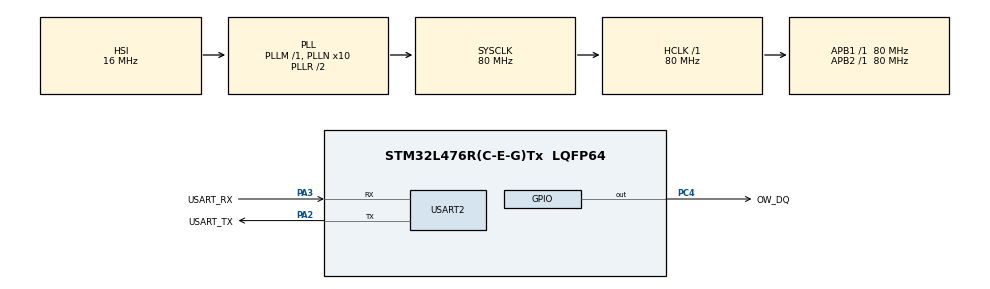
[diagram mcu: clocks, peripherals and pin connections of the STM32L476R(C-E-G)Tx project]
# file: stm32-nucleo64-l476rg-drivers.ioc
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Mcu.Family=STM32L4
Mcu.Name=STM32L476R(C-E-G)Tx
Mcu.Package=LQFP64
NVIC.PriorityGroup=NVIC_PRIORITYGROUP_4
PA13\ (JTMS-SWDIO).GPIO_Label=TMS
PA13\ (JTMS-SWDIO).Mode=Serial_Wire
PA13\ (JTMS-SWDIO).Signal=SYS_JTMS-SWDIO
PA14\ (JTCK-SWCLK).GPIO_Label=TCK
PA14\ (JTCK-SWCLK).Mode=Serial_Wire
PA14\ (JTCK-SWCLK).Signal=SYS_JTCK-SWCLK
PA2.GPIO_Label=USART_TX
PA2.GPIO_Mode=GPIO_MODE_AF_PP
PA2.GPIO_PuPd=GPIO_NOPULL
PA2.GPIO_Speed=GPIO_SPEED_FREQ_VERY_HIGH
PA2.Mode=Asynchronous
PA2.Signal=USART2_TX
PA3.GPIO_Label=USART_RX
PA3.GPIO_Mode=GPIO_MODE_AF_PP
PA3.GPIO_PuPd=GPIO_NOPULL
PA3.GPIO_Speed=GPIO_SPEED_FREQ_VERY_HIGH
PA3.Mode=Asynchronous
PA3.Signal=USART2_RX
PB3\ (JTDO-TRACESWO).GPIO_Label=SWO
PB3\ (JTDO-TRACESWO).Signal=SYS_JTDO-SWO
PC14-OSC32_IN\ (PC14).Mode=LSE-External-Oscillator
PC14-OSC32_IN\ (PC14).Signal=RCC_OSC32_IN
PC15-OSC32_OUT\ (PC15).Mode=LSE-External-Oscillator
PC15-OSC32_OUT\ (PC15).Signal=RCC_OSC32_OUT
PC4.GPIO_Label=OW_DQ
PC4.GPIO_ModeDefaultOutputPP=GPIO_MODE_OUTPUT_OD
PC4.GPIO_PuPd=GPIO_NOPULL
PC4.PinState=GPIO_PIN_SET
PC4.Signal=GPIO_Output
PH0-OSC_IN\ (PH0).Signal=RCC_OSC_IN
PH1-OSC_OUT\ (PH1).Signal=RCC_OSC_OUT
ProjectManager.HeapSize=0x200
ProjectManager.StackSize=0x400
ProjectManager.TargetToolchain=CMake
RCC.ADCFreq_Value=64000000
RCC.AHBFreq_Value=80000000
RCC.APB1Freq_Value=80000000
RCC.APB1TimFreq_Value=80000000
RCC.APB2Freq_Value=80000000
RCC.APB2TimFreq_Value=80000000
RCC.CortexFreq_Value=80000000
RCC.HCLKFreq_Value=80000000
RCC.HSE_VALUE=8000000
RCC.HSI_VALUE=16000000
RCC.MSI_VALUE=4000000
RCC.PLLN=10
RCC.PLLSourceVirtual=RCC_PLLSOURCE_HSI
RCC.PREFETCH_ENABLE=1
RCC.SYSCLKFreq_VALUE=80000000
RCC.SYSCLKSource=RCC_SYSCLKSOURCE_PLLCLK
RCC.USBFreq_Value=64000000
RCC.VCOOutputFreq_Value=160000000
USART2.VirtualMode-Asynchronous=VM_ASYNC
board=NUCLEO-L476RG

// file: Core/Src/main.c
/* USER CODE BEGIN Header */
/**
 ******************************************************************************
 * @file           : main.c
 * @brief          : Main program body
 ******************************************************************************
 * @attention
 *
 * Copyright (c) 2025 STMicroelectronics.
 * All rights reserved.
 *
 * This software is licensed under terms that can be found in the LICENSE file
 * in the root directory of this software component.
 * If no LICENSE file comes with this software, it is provided AS-IS.
 *
 ******************************************************************************
 */
/* USER CODE END Header */
#include "main.h"
#include "gpio.h"
#include "usart.h"

/* USER CODE BEGIN Includes */
#include "ds18b20.h"
#include "one_wire.h"
#include <stdint.h>
#include <stdio.h>

/* USER CODE END Includes */

/* USER CODE BEGIN PD */
#define MAX_ONE_WIRE_DEVICES 10
/* USER CODE END PD */

void SystemClock_Config(void);

/* USER CODE BEGIN 0 */
// Printf redirect to UART
int _write(int file, char *ptr, int len) {
  HAL_UART_Transmit(&huart2, (uint8_t *)ptr, len, HAL_MAX_DELAY);
  return len;
}

/* USER CODE END 0 */

int main(void) {

  /* MCU Configuration--------------------------------------------------------*/

  /* Reset of all peripherals, Initializes the Flash interface and the Systick.
   */
  HAL_Init();

  /* USER CODE BEGIN Init */
  ds18b20_init();
  /* USER CODE END Init */

  /* Configure the system clock */
  SystemClock_Config();

  /* Initialize all configured peripherals */
  MX_GPIO_Init();
  MX_USART2_UART_Init();
  /* USER CODE BEGIN 2 */
  uint8_t rom_codes[MAX_ONE_WIRE_DEVICES][8];
  int8_t device_count = 0;
  int8_t result;
  uint8_t scratchpad[DS18B20_SCRATCHPAD_BYTES];
  float temperature;

  one_wire_search_rom_reset();

  while ((result = one_wire_search_rom(rom_codes[device_count])) == 1) {
    printf("Device %d ROM: ", device_count);
    for (int i = 0; i < 8; i++) {
      printf("%02X ", rom_codes[device_count][i]);
    }
    printf("\r\n");

    device_count++;
    if (device_count >= MAX_ONE_WIRE_DEVICES) {
      break;
    }
  }

  if (result < 0) {
    printf("Search error occurred\r\n");
  } else {
    printf("Found %d one-wire device(s)\r\n", device_count);
  }
  /* USER CODE END 2 */

  /* Infinite loop */
  while (1) {

    /* USER CODE BEGIN 3 */
    // Start conversion
    if (ds18b20_start_conversion(rom_codes[0]) == 0) {
      printf("Conversion started...\n");
    }

    if (ds18b20_read_scratchpad(rom_codes[0], scratchpad) == 0) {
      printf("SCRATCHPAD: ");
      for (int i = 0; i < 9; i++) {
        printf("%02X ", scratchpad[i]);
      }
      printf("\r\n");
    }

    // Read temperature
    // Wait for ready (750ms for 12 bit resolution)
    HAL_Delay(750);
    if (ds18b20_read_temperature(rom_codes[0], &temperature) == 0) {
      printf("Temperature: %.2f°C\n", temperature);
    }
  }
  /* USER CODE END 3 */
}

void SystemClock_Config(void) {
  RCC_OscInitTypeDef RCC_OscInitStruct = {0};
  RCC_ClkInitTypeDef RCC_ClkInitStruct = {0};

  /** Configure the main internal regulator output voltage
   */
  if (HAL_PWREx_ControlVoltageScaling(PWR_REGULATOR_VOLTAGE_SCALE1) != HAL_OK) {
    Error_Handler();
  }

  /** Initializes the RCC Oscillators according to the specified parameters
   * in the RCC_OscInitTypeDef structure.
   */
  RCC_OscInitStruct.OscillatorType = RCC_OSCILLATORTYPE_HSI;
  RCC_OscInitStruct.HSIState = RCC_HSI_ON;
  RCC_OscInitStruct.HSICalibrationValue = RCC_HSICALIBRATION_DEFAULT;
  RCC_OscInitStruct.PLL.PLLState = RCC_PLL_ON;
  RCC_OscInitStruct.PLL.PLLSource = RCC_PLLSOURCE_HSI;
  RCC_OscInitStruct.PLL.PLLM = 1;
  RCC_OscInitStruct.PLL.PLLN = 10;
  RCC_OscInitStruct.PLL.PLLP = RCC_PLLP_DIV7;
  RCC_OscInitStruct.PLL.PLLQ = RCC_PLLQ_DIV2;
  RCC_OscInitStruct.PLL.PLLR = RCC_PLLR_DIV2;
  if (HAL_RCC_OscConfig(&RCC_OscInitStruct) != HAL_OK) {
    Error_Handler();
  }

  /** Initializes the CPU, AHB and APB buses clocks
   */
  RCC_ClkInitStruct.ClockType = RCC_CLOCKTYPE_HCLK | RCC_CLOCKTYPE_SYSCLK |
                                RCC_CLOCKTYPE_PCLK1 | RCC_CLOCKTYPE_PCLK2;
  RCC_ClkInitStruct.SYSCLKSource = RCC_SYSCLKSOURCE_PLLCLK;
  RCC_ClkInitStruct.AHBCLKDivider = RCC_SYSCLK_DIV1;
  RCC_ClkInitStruct.APB1CLKDivider = RCC_HCLK_DIV1;
  RCC_ClkInitStruct.APB2CLKDivider = RCC_HCLK_DIV1;

  if (HAL_RCC_ClockConfig(&RCC_ClkInitStruct, FLASH_LATENCY_4) != HAL_OK) {
    Error_Handler();
  }
}

void Error_Handler(void) {
  __disable_irq();
  while (1) {
  }
}
#ifdef USE_FULL_ASSERT
/**
 * @brief  Reports the name of the source file and the source line number
 *         where the assert_param error has occurred.
 * @param  file: pointer to the source file name
 * @param  line: assert_param error line source number
 * @retval None
 */
void assert_failed(uint8_t *file, uint32_t line) {
  /* USER CODE BEGIN 6 */
  /* User can add his own implementation to report the file name and line
     number, ex: printf("Wrong parameters value: file %s on line %d\r\n", file,
     line) */
  /* USER CODE END 6 */
}
#endif /* USE_FULL_ASSERT */
